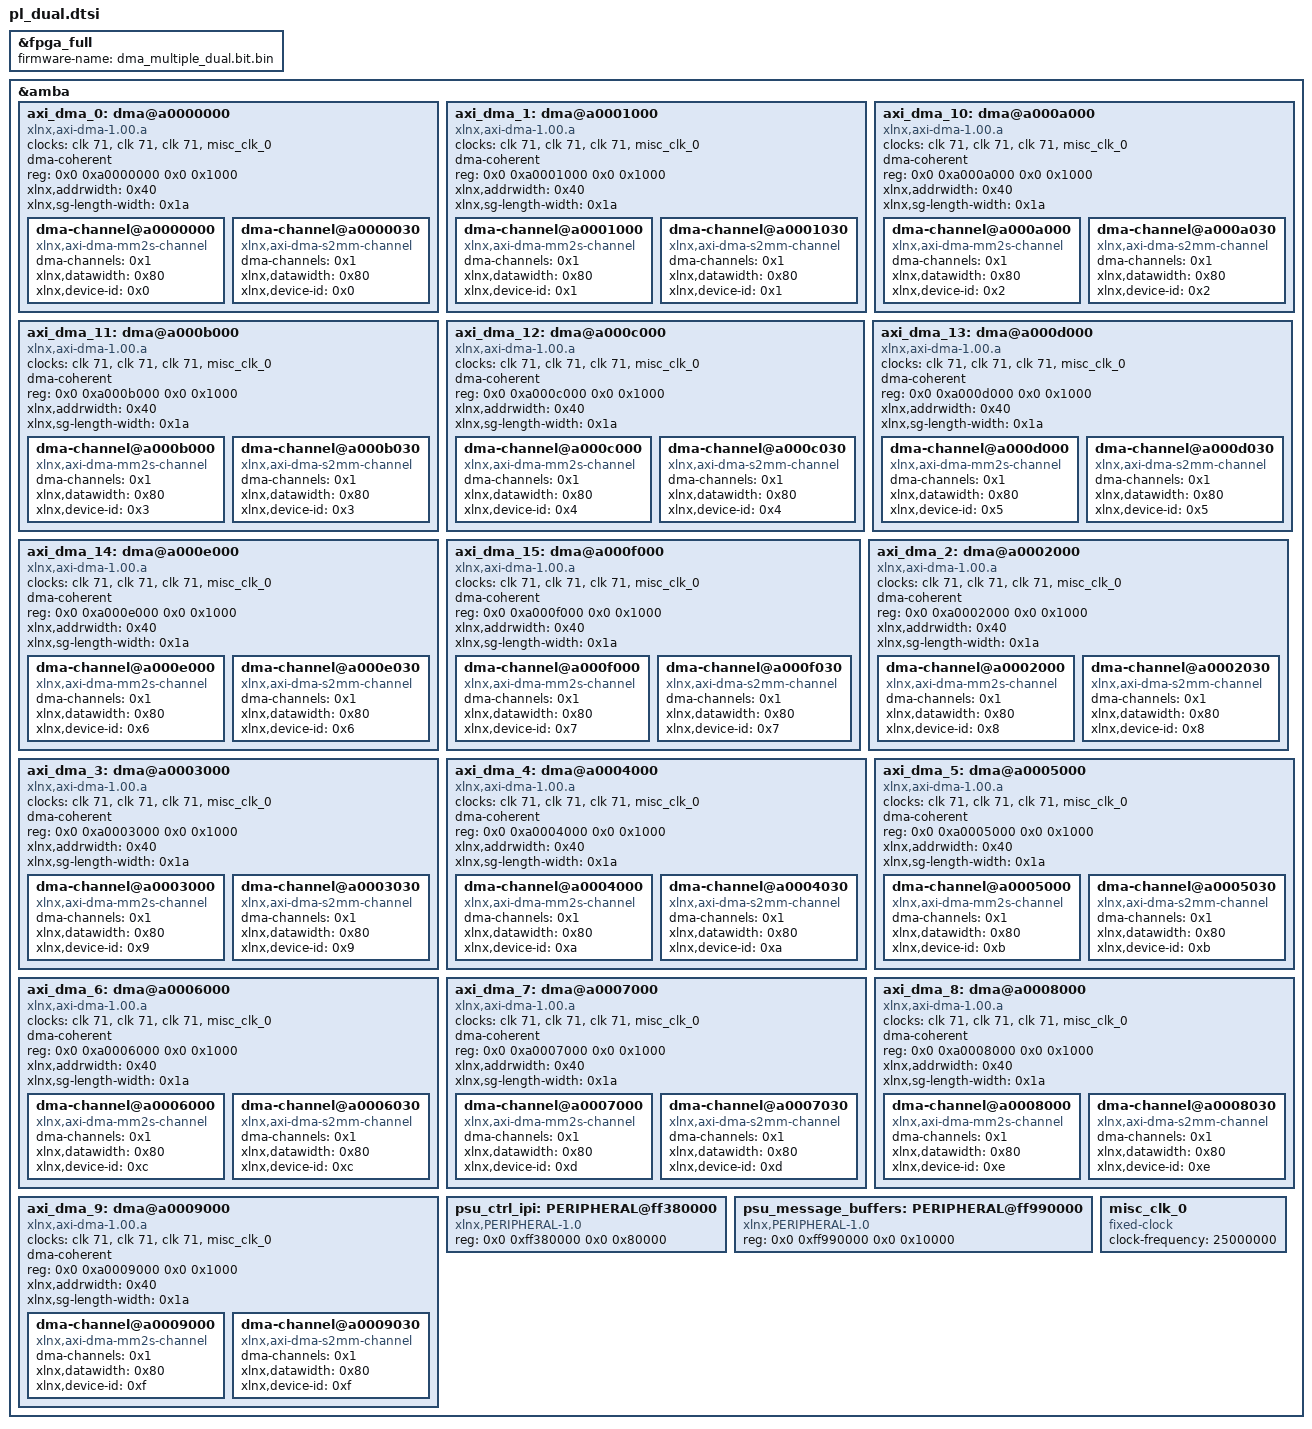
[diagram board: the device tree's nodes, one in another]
/*
 * CAUTION: This file is automatically generated by Xilinx.
 * Version:  
 * Today is: Thu Mar 21 13:52:22 2019
 */


/dts-v1/;
/plugin/;
/ {
	fragment@0 {
		target = <&fpga_full>;
		overlay0: __overlay__ {
			#address-cells = <2>;
			#size-cells = <2>;
			firmware-name = "dma_multiple_dual.bit.bin";
		};
	};
	fragment@1 {
		target = <&amba>;
		overlay1: __overlay__ {
			axi_dma_0: dma@a0000000 {
				#dma-cells = <1>;
				clock-names = "s_axi_lite_aclk", "m_axi_sg_aclk", "m_axi_mm2s_aclk", "m_axi_s2mm_aclk";
				clocks = <&clk 71>, <&clk 71>, <&clk 71>, <&misc_clk_0>;
				compatible = "xlnx,axi-dma-1.00.a";
				dma-coherent ;
				reg = <0x0 0xa0000000 0x0 0x1000>;
				xlnx,addrwidth = <0x40>;
				xlnx,sg-length-width = <0x1a>;
				dma-channel@a0000000 {
					compatible = "xlnx,axi-dma-mm2s-channel";
					dma-channels = <0x1>;
					xlnx,datawidth = <0x80>;
					xlnx,device-id = <0x0>;
				};
				dma-channel@a0000030 {
					compatible = "xlnx,axi-dma-s2mm-channel";
					dma-channels = <0x1>;
					xlnx,datawidth = <0x80>;
					xlnx,device-id = <0x0>;
				};
			};
			axi_dma_1: dma@a0001000 {
				#dma-cells = <1>;
				clock-names = "s_axi_lite_aclk", "m_axi_sg_aclk", "m_axi_mm2s_aclk", "m_axi_s2mm_aclk";
				clocks = <&clk 71>, <&clk 71>, <&clk 71>, <&misc_clk_0>;
				compatible = "xlnx,axi-dma-1.00.a";
				dma-coherent ;
				reg = <0x0 0xa0001000 0x0 0x1000>;
				xlnx,addrwidth = <0x40>;
				xlnx,sg-length-width = <0x1a>;
				dma-channel@a0001000 {
					compatible = "xlnx,axi-dma-mm2s-channel";
					dma-channels = <0x1>;
					xlnx,datawidth = <0x80>;
					xlnx,device-id = <0x1>;
				};
				dma-channel@a0001030 {
					compatible = "xlnx,axi-dma-s2mm-channel";
					dma-channels = <0x1>;
					xlnx,datawidth = <0x80>;
					xlnx,device-id = <0x1>;
				};
			};
			axi_dma_10: dma@a000a000 {
				#dma-cells = <1>;
				clock-names = "s_axi_lite_aclk", "m_axi_sg_aclk", "m_axi_mm2s_aclk", "m_axi_s2mm_aclk";
				clocks = <&clk 71>, <&clk 71>, <&clk 71>, <&misc_clk_0>;
				compatible = "xlnx,axi-dma-1.00.a";
				dma-coherent ;
				reg = <0x0 0xa000a000 0x0 0x1000>;
				xlnx,addrwidth = <0x40>;
				xlnx,sg-length-width = <0x1a>;
				dma-channel@a000a000 {
					compatible = "xlnx,axi-dma-mm2s-channel";
					dma-channels = <0x1>;
					xlnx,datawidth = <0x80>;
					xlnx,device-id = <0x2>;
				};
				dma-channel@a000a030 {
					compatible = "xlnx,axi-dma-s2mm-channel";
					dma-channels = <0x1>;
					xlnx,datawidth = <0x80>;
					xlnx,device-id = <0x2>;
				};
			};
			axi_dma_11: dma@a000b000 {
				#dma-cells = <1>;
				clock-names = "s_axi_lite_aclk", "m_axi_sg_aclk", "m_axi_mm2s_aclk", "m_axi_s2mm_aclk";
				clocks = <&clk 71>, <&clk 71>, <&clk 71>, <&misc_clk_0>;
				compatible = "xlnx,axi-dma-1.00.a";
				dma-coherent ;
				reg = <0x0 0xa000b000 0x0 0x1000>;
				xlnx,addrwidth = <0x40>;
				xlnx,sg-length-width = <0x1a>;
				dma-channel@a000b000 {
					compatible = "xlnx,axi-dma-mm2s-channel";
					dma-channels = <0x1>;
					xlnx,datawidth = <0x80>;
					xlnx,device-id = <0x3>;
				};
				dma-channel@a000b030 {
					compatible = "xlnx,axi-dma-s2mm-channel";
					dma-channels = <0x1>;
					xlnx,datawidth = <0x80>;
					xlnx,device-id = <0x3>;
				};
			};
			axi_dma_12: dma@a000c000 {
				#dma-cells = <1>;
				clock-names = "s_axi_lite_aclk", "m_axi_sg_aclk", "m_axi_mm2s_aclk", "m_axi_s2mm_aclk";
				clocks = <&clk 71>, <&clk 71>, <&clk 71>, <&misc_clk_0>;
				compatible = "xlnx,axi-dma-1.00.a";
				dma-coherent ;
				reg = <0x0 0xa000c000 0x0 0x1000>;
				xlnx,addrwidth = <0x40>;
				xlnx,sg-length-width = <0x1a>;
				dma-channel@a000c000 {
					compatible = "xlnx,axi-dma-mm2s-channel";
					dma-channels = <0x1>;
					xlnx,datawidth = <0x80>;
					xlnx,device-id = <0x4>;
				};
				dma-channel@a000c030 {
					compatible = "xlnx,axi-dma-s2mm-channel";
					dma-channels = <0x1>;
					xlnx,datawidth = <0x80>;
					xlnx,device-id = <0x4>;
				};
			};
			axi_dma_13: dma@a000d000 {
				#dma-cells = <1>;
				clock-names = "s_axi_lite_aclk", "m_axi_sg_aclk", "m_axi_mm2s_aclk", "m_axi_s2mm_aclk";
				clocks = <&clk 71>, <&clk 71>, <&clk 71>, <&misc_clk_0>;
				compatible = "xlnx,axi-dma-1.00.a";
				dma-coherent ;
				reg = <0x0 0xa000d000 0x0 0x1000>;
				xlnx,addrwidth = <0x40>;
				xlnx,sg-length-width = <0x1a>;
				dma-channel@a000d000 {
					compatible = "xlnx,axi-dma-mm2s-channel";
					dma-channels = <0x1>;
					xlnx,datawidth = <0x80>;
					xlnx,device-id = <0x5>;
				};
				dma-channel@a000d030 {
					compatible = "xlnx,axi-dma-s2mm-channel";
					dma-channels = <0x1>;
					xlnx,datawidth = <0x80>;
					xlnx,device-id = <0x5>;
				};
			};
			axi_dma_14: dma@a000e000 {
				#dma-cells = <1>;
				clock-names = "s_axi_lite_aclk", "m_axi_sg_aclk", "m_axi_mm2s_aclk", "m_axi_s2mm_aclk";
				clocks = <&clk 71>, <&clk 71>, <&clk 71>, <&misc_clk_0>;
				compatible = "xlnx,axi-dma-1.00.a";
				dma-coherent ;
				reg = <0x0 0xa000e000 0x0 0x1000>;
				xlnx,addrwidth = <0x40>;
				xlnx,sg-length-width = <0x1a>;
				dma-channel@a000e000 {
					compatible = "xlnx,axi-dma-mm2s-channel";
					dma-channels = <0x1>;
					xlnx,datawidth = <0x80>;
					xlnx,device-id = <0x6>;
				};
				dma-channel@a000e030 {
					compatible = "xlnx,axi-dma-s2mm-channel";
					dma-channels = <0x1>;
					xlnx,datawidth = <0x80>;
					xlnx,device-id = <0x6>;
				};
			};
			axi_dma_15: dma@a000f000 {
				#dma-cells = <1>;
				clock-names = "s_axi_lite_aclk", "m_axi_sg_aclk", "m_axi_mm2s_aclk", "m_axi_s2mm_aclk";
				clocks = <&clk 71>, <&clk 71>, <&clk 71>, <&misc_clk_0>;
				compatible = "xlnx,axi-dma-1.00.a";
				dma-coherent ;
				reg = <0x0 0xa000f000 0x0 0x1000>;
				xlnx,addrwidth = <0x40>;
				xlnx,sg-length-width = <0x1a>;
				dma-channel@a000f000 {
					compatible = "xlnx,axi-dma-mm2s-channel";
					dma-channels = <0x1>;
					xlnx,datawidth = <0x80>;
					xlnx,device-id = <0x7>;
				};
				dma-channel@a000f030 {
					compatible = "xlnx,axi-dma-s2mm-channel";
					dma-channels = <0x1>;
					xlnx,datawidth = <0x80>;
					xlnx,device-id = <0x7>;
				};
			};
			axi_dma_2: dma@a0002000 {
				#dma-cells = <1>;
				clock-names = "s_axi_lite_aclk", "m_axi_sg_aclk", "m_axi_mm2s_aclk", "m_axi_s2mm_aclk";
				clocks = <&clk 71>, <&clk 71>, <&clk 71>, <&misc_clk_0>;
				compatible = "xlnx,axi-dma-1.00.a";
				dma-coherent ;
				reg = <0x0 0xa0002000 0x0 0x1000>;
				xlnx,addrwidth = <0x40>;
				xlnx,sg-length-width = <0x1a>;
				dma-channel@a0002000 {
					compatible = "xlnx,axi-dma-mm2s-channel";
					dma-channels = <0x1>;
					xlnx,datawidth = <0x80>;
					xlnx,device-id = <0x8>;
				};
				dma-channel@a0002030 {
					compatible = "xlnx,axi-dma-s2mm-channel";
					dma-channels = <0x1>;
					xlnx,datawidth = <0x80>;
					xlnx,device-id = <0x8>;
				};
			};
			axi_dma_3: dma@a0003000 {
				#dma-cells = <1>;
				clock-names = "s_axi_lite_aclk", "m_axi_sg_aclk", "m_axi_mm2s_aclk", "m_axi_s2mm_aclk";
				clocks = <&clk 71>, <&clk 71>, <&clk 71>, <&misc_clk_0>;
				compatible = "xlnx,axi-dma-1.00.a";
				dma-coherent ;
				reg = <0x0 0xa0003000 0x0 0x1000>;
				xlnx,addrwidth = <0x40>;
				xlnx,sg-length-width = <0x1a>;
				dma-channel@a0003000 {
					compatible = "xlnx,axi-dma-mm2s-channel";
					dma-channels = <0x1>;
					xlnx,datawidth = <0x80>;
					xlnx,device-id = <0x9>;
				};
				dma-channel@a0003030 {
					compatible = "xlnx,axi-dma-s2mm-channel";
					dma-channels = <0x1>;
					xlnx,datawidth = <0x80>;
					xlnx,device-id = <0x9>;
				};
			};
			axi_dma_4: dma@a0004000 {
				#dma-cells = <1>;
				clock-names = "s_axi_lite_aclk", "m_axi_sg_aclk", "m_axi_mm2s_aclk", "m_axi_s2mm_aclk";
				clocks = <&clk 71>, <&clk 71>, <&clk 71>, <&misc_clk_0>;
				compatible = "xlnx,axi-dma-1.00.a";
				dma-coherent ;
				reg = <0x0 0xa0004000 0x0 0x1000>;
				xlnx,addrwidth = <0x40>;
				xlnx,sg-length-width = <0x1a>;
				dma-channel@a0004000 {
					compatible = "xlnx,axi-dma-mm2s-channel";
					dma-channels = <0x1>;
					xlnx,datawidth = <0x80>;
					xlnx,device-id = <0xa>;
				};
				dma-channel@a0004030 {
					compatible = "xlnx,axi-dma-s2mm-channel";
					dma-channels = <0x1>;
					xlnx,datawidth = <0x80>;
					xlnx,device-id = <0xa>;
				};
			};
			axi_dma_5: dma@a0005000 {
				#dma-cells = <1>;
				clock-names = "s_axi_lite_aclk", "m_axi_sg_aclk", "m_axi_mm2s_aclk", "m_axi_s2mm_aclk";
				clocks = <&clk 71>, <&clk 71>, <&clk 71>, <&misc_clk_0>;
				compatible = "xlnx,axi-dma-1.00.a";
				dma-coherent ;
				reg = <0x0 0xa0005000 0x0 0x1000>;
				xlnx,addrwidth = <0x40>;
				xlnx,sg-length-width = <0x1a>;
				dma-channel@a0005000 {
					compatible = "xlnx,axi-dma-mm2s-channel";
					dma-channels = <0x1>;
					xlnx,datawidth = <0x80>;
					xlnx,device-id = <0xb>;
				};
				dma-channel@a0005030 {
					compatible = "xlnx,axi-dma-s2mm-channel";
					dma-channels = <0x1>;
					xlnx,datawidth = <0x80>;
					xlnx,device-id = <0xb>;
				};
			};
			axi_dma_6: dma@a0006000 {
				#dma-cells = <1>;
				clock-names = "s_axi_lite_aclk", "m_axi_sg_aclk", "m_axi_mm2s_aclk", "m_axi_s2mm_aclk";
				clocks = <&clk 71>, <&clk 71>, <&clk 71>, <&misc_clk_0>;
				compatible = "xlnx,axi-dma-1.00.a";
				dma-coherent ;
				reg = <0x0 0xa0006000 0x0 0x1000>;
				xlnx,addrwidth = <0x40>;
				xlnx,sg-length-width = <0x1a>;
				dma-channel@a0006000 {
					compatible = "xlnx,axi-dma-mm2s-channel";
					dma-channels = <0x1>;
					xlnx,datawidth = <0x80>;
					xlnx,device-id = <0xc>;
				};
				dma-channel@a0006030 {
					compatible = "xlnx,axi-dma-s2mm-channel";
					dma-channels = <0x1>;
					xlnx,datawidth = <0x80>;
					xlnx,device-id = <0xc>;
				};
			};
			axi_dma_7: dma@a0007000 {
				#dma-cells = <1>;
				clock-names = "s_axi_lite_aclk", "m_axi_sg_aclk", "m_axi_mm2s_aclk", "m_axi_s2mm_aclk";
				clocks = <&clk 71>, <&clk 71>, <&clk 71>, <&misc_clk_0>;
				compatible = "xlnx,axi-dma-1.00.a";
				dma-coherent ;
				reg = <0x0 0xa0007000 0x0 0x1000>;
				xlnx,addrwidth = <0x40>;
				xlnx,sg-length-width = <0x1a>;
				dma-channel@a0007000 {
					compatible = "xlnx,axi-dma-mm2s-channel";
					dma-channels = <0x1>;
					xlnx,datawidth = <0x80>;
					xlnx,device-id = <0xd>;
				};
				dma-channel@a0007030 {
					compatible = "xlnx,axi-dma-s2mm-channel";
					dma-channels = <0x1>;
					xlnx,datawidth = <0x80>;
					xlnx,device-id = <0xd>;
				};
			};
			axi_dma_8: dma@a0008000 {
				#dma-cells = <1>;
				clock-names = "s_axi_lite_aclk", "m_axi_sg_aclk", "m_axi_mm2s_aclk", "m_axi_s2mm_aclk";
				clocks = <&clk 71>, <&clk 71>, <&clk 71>, <&misc_clk_0>;
				compatible = "xlnx,axi-dma-1.00.a";
				dma-coherent ;
				reg = <0x0 0xa0008000 0x0 0x1000>;
				xlnx,addrwidth = <0x40>;
				xlnx,sg-length-width = <0x1a>;
				dma-channel@a0008000 {
					compatible = "xlnx,axi-dma-mm2s-channel";
					dma-channels = <0x1>;
					xlnx,datawidth = <0x80>;
					xlnx,device-id = <0xe>;
				};
				dma-channel@a0008030 {
					compatible = "xlnx,axi-dma-s2mm-channel";
					dma-channels = <0x1>;
					xlnx,datawidth = <0x80>;
					xlnx,device-id = <0xe>;
				};
			};
			axi_dma_9: dma@a0009000 {
				#dma-cells = <1>;
				clock-names = "s_axi_lite_aclk", "m_axi_sg_aclk", "m_axi_mm2s_aclk", "m_axi_s2mm_aclk";
				clocks = <&clk 71>, <&clk 71>, <&clk 71>, <&misc_clk_0>;
				compatible = "xlnx,axi-dma-1.00.a";
				dma-coherent ;
				reg = <0x0 0xa0009000 0x0 0x1000>;
				xlnx,addrwidth = <0x40>;
				xlnx,sg-length-width = <0x1a>;
				dma-channel@a0009000 {
					compatible = "xlnx,axi-dma-mm2s-channel";
					dma-channels = <0x1>;
					xlnx,datawidth = <0x80>;
					xlnx,device-id = <0xf>;
				};
				dma-channel@a0009030 {
					compatible = "xlnx,axi-dma-s2mm-channel";
					dma-channels = <0x1>;
					xlnx,datawidth = <0x80>;
					xlnx,device-id = <0xf>;
				};
			};
			psu_ctrl_ipi: PERIPHERAL@ff380000 {
				compatible = "xlnx,PERIPHERAL-1.0";
				reg = <0x0 0xff380000 0x0 0x80000>;
			};
			psu_message_buffers: PERIPHERAL@ff990000 {
				compatible = "xlnx,PERIPHERAL-1.0";
				reg = <0x0 0xff990000 0x0 0x10000>;
			};
			misc_clk_0: misc_clk_0 {
				#clock-cells = <0>;
				clock-frequency = <25000000>;
				compatible = "fixed-clock";
			};
		};
	};
};
